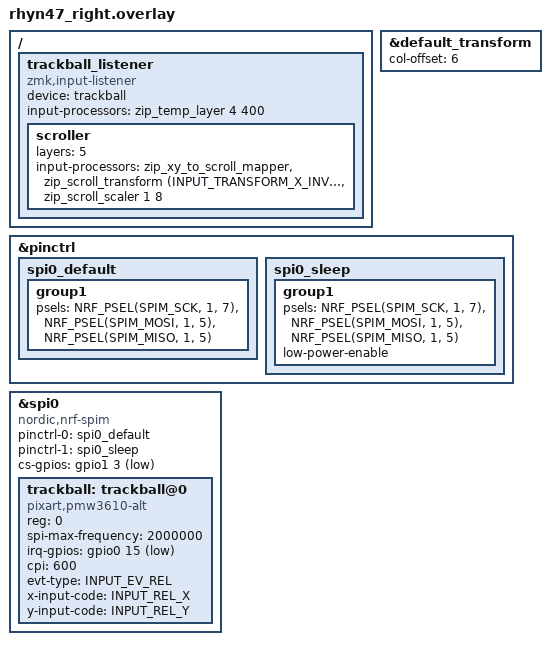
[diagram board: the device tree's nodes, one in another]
/*
 * rhyn47 右手（セントラル・トラックボールあり）
 *
 * 右がセントラルなので zmk,input-split によるペリフェラル→セントラル転送は不要。
 * SPI + PMW3610 + input-listener をそのまま書く（実装ノート §7）。
 */

#include "rhyn47.dtsi"
#include <input/processors.dtsi>
#include <dt-bindings/zmk/input_transform.h>
#include <zephyr/dt-bindings/input/input-event-codes.h>

/* 右手の物理列0-5 を論理列6-11 へ */
&default_transform {
    col-offset = <6>;
};

/*
 * 3線 SPI: PMW3610 の SDIO は双方向1本なので MOSI/MISO を同じ P1.05 に割り当てる。
 *
 * ⚠ nRF52840 は SPIM0 と TWIM0 が周辺 ID を共有する。Zephyr の base xiao_ble.dts で
 *   &i2c0 が有効だとビルドが落ちるので、その場合は &spi0 → &spi3 に置換
 *   （SPIM3 は TWI と共有しない。pinctrl はどのピンにもルーティング可）。
 */
&pinctrl {
    spi0_default: spi0_default {
        group1 {
            psels = <NRF_PSEL(SPIM_SCK,  1, 7)>,   // SCLK = P1.07
                    <NRF_PSEL(SPIM_MOSI, 1, 5)>,   // SDIO = P1.05
                    <NRF_PSEL(SPIM_MISO, 1, 5)>;   //  〃   （同一ピン）
        };
    };

    spi0_sleep: spi0_sleep {
        group1 {
            psels = <NRF_PSEL(SPIM_SCK,  1, 7)>,
                    <NRF_PSEL(SPIM_MOSI, 1, 5)>,
                    <NRF_PSEL(SPIM_MISO, 1, 5)>;
            low-power-enable;
        };
    };
};

&spi0 {
    status = "okay";
    compatible = "nordic,nrf-spim";
    pinctrl-0 = <&spi0_default>;
    pinctrl-1 = <&spi0_sleep>;
    pinctrl-names = "default", "sleep";
    cs-gpios = <&gpio1 3 GPIO_ACTIVE_LOW>;   // nCS = P1.03

    trackball: trackball@0 {
        status = "okay";
        /* ⚠ compatible / CONFIG 名は採用フォーク（badjeff/zmk-pmw3610-driver）の
           README と必ず突き合わせる。west.yml・rhyn47_right.conf と3点セット。 */
        compatible = "pixart,pmw3610-alt";
        reg = <0>;
        spi-max-frequency = <2000000>;   /* PMW3610 は 2MHz 上限 */

        /* MOTION = P0.15。NRESET は外付け10kで3.3Vプルアップ固定なので GPIO 不要 */
        irq-gpios = <&gpio0 15 (GPIO_ACTIVE_LOW | GPIO_PULL_UP)>;

        cpi = <600>;   /* 初期値。実機で調整 */

        /* 向きは 14mm ボール＋実機の取り付け角で決まる。実機で確認して有効化 */
        // swap-xy;
        // invert-x;
        // invert-y;

        evt-type = <INPUT_EV_REL>;
        x-input-code = <INPUT_REL_X>;
        y-input-code = <INPUT_REL_Y>;
    };
};

/ {
    trackball_listener {
        compatible = "zmk,input-listener";
        device = <&trackball>;

        /*
         * QMK 版の set_auto_mouse_layer(_MOUSE) 相当。
         * ボールを動かすと MOUSE レイヤ(4)が一時的に有効、停止 400ms で解除。
         */
        input-processors = <&zip_temp_layer 4 400>;

        /*
         * QMK 版の rhyn47_lptb_set_scroll_layer(_SCROLL) 相当。
         * SCROLL レイヤ(5)の間は XY をスクロールに読み替える。
         * transform は pointing_device_task_user() の v/h 反転（ナチュラルスクロール）に対応。
         */
        scroller {
            layers = <5>;
            input-processors
                = <&zip_xy_to_scroll_mapper>
                , <&zip_scroll_transform (INPUT_TRANSFORM_X_INVERT | INPUT_TRANSFORM_Y_INVERT)>
                , <&zip_scroll_scaler 1 8>;
        };
    };
};
